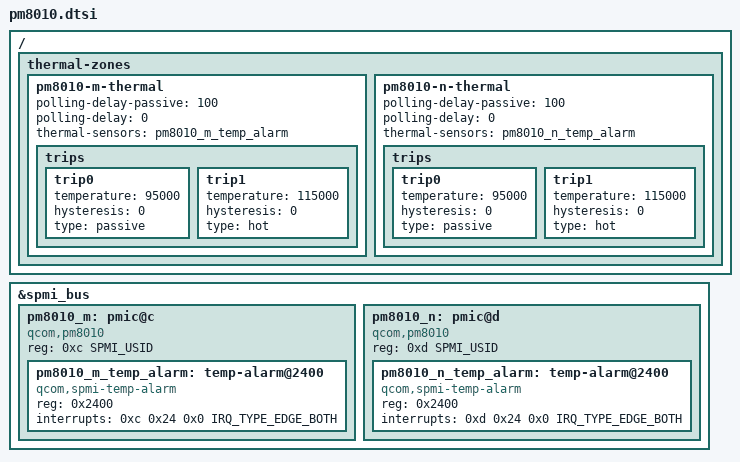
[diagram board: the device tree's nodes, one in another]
// SPDX-License-Identifier: BSD-3-Clause
/*
 * Copyright (c) 2022, Linaro Limited
 */

#include <dt-bindings/interrupt-controller/irq.h>
#include <dt-bindings/spmi/spmi.h>

/ {
	thermal-zones {
		pm8010-m-thermal {
			polling-delay-passive = <100>;
			polling-delay = <0>;

			thermal-sensors = <&pm8010_m_temp_alarm>;

			trips {
				trip0 {
					temperature = <95000>;
					hysteresis = <0>;
					type = "passive";
				};

				trip1 {
					temperature = <115000>;
					hysteresis = <0>;
					type = "hot";
				};
			};
		};

		pm8010-n-thermal {
			polling-delay-passive = <100>;
			polling-delay = <0>;

			thermal-sensors = <&pm8010_n_temp_alarm>;

			trips {
				trip0 {
					temperature = <95000>;
					hysteresis = <0>;
					type = "passive";
				};

				trip1 {
					temperature = <115000>;
					hysteresis = <0>;
					type = "hot";
				};
			};
		};
	};
};


&spmi_bus {
	pm8010_m: pmic@c {
		compatible = "qcom,pm8010", "qcom,spmi-pmic";
		reg = <0xc SPMI_USID>;
		#address-cells = <1>;
		#size-cells = <0>;

		pm8010_m_temp_alarm: temp-alarm@2400 {
			compatible = "qcom,spmi-temp-alarm";
			reg = <0x2400>;
			interrupts = <0xc 0x24 0x0 IRQ_TYPE_EDGE_BOTH>;
			#thermal-sensor-cells = <0>;
		};
	};

	pm8010_n: pmic@d {
		compatible = "qcom,pm8010", "qcom,spmi-pmic";
		reg = <0xd SPMI_USID>;
		#address-cells = <1>;
		#size-cells = <0>;

		pm8010_n_temp_alarm: temp-alarm@2400 {
			compatible = "qcom,spmi-temp-alarm";
			reg = <0x2400>;
			interrupts = <0xd 0x24 0x0 IRQ_TYPE_EDGE_BOTH>;
			#thermal-sensor-cells = <0>;
		};
	};
};
